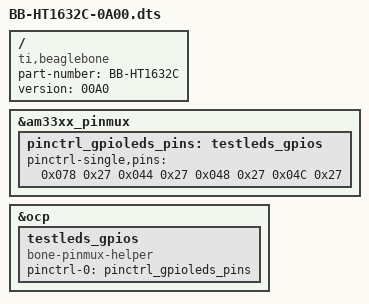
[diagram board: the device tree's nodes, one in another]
/*
 #define DATA 28 //1_28
 #define WR 17 //1_17
 #define CS 16 //1_16
 #define CLK 19 // 1_18
*/

/dts-v1/;
/plugin/;

/ {
        compatible = "ti,beaglebone", "ti,beaglebone-black";

    /* identification */
        part-number = "BB-HT1632C";
        version = "00A0";

        fragment@0 {
            target = <&am33xx_pinmux>;
            __overlay__ {
                    pinctrl_gpioleds_pins: testleds_gpios {
                        pinctrl-single,pins = <
                                0x078 0x27 /* P8_12 = gpio1[28] */
                                0x044 0x27 /* P8_23 = gpio1[17] */
                                0x048 0x27 /* P8_15 = gpio1[16] */
                                0x04C 0x27 /* P8_16 = gpio1[19] */
                        >;
                    };
            };
        };

    fragment@1 {
        target = <&ocp>;
        __overlay__ {
            #address-cells = <1>;
            #size-cells = <1>;
            testleds_gpios {
                compatible = "bone-pinmux-helper";
                pinctrl-names = "default";
                pinctrl-0 = <&pinctrl_gpioleds_pins>;
                status = "okay";
            };
        };
    };

};
